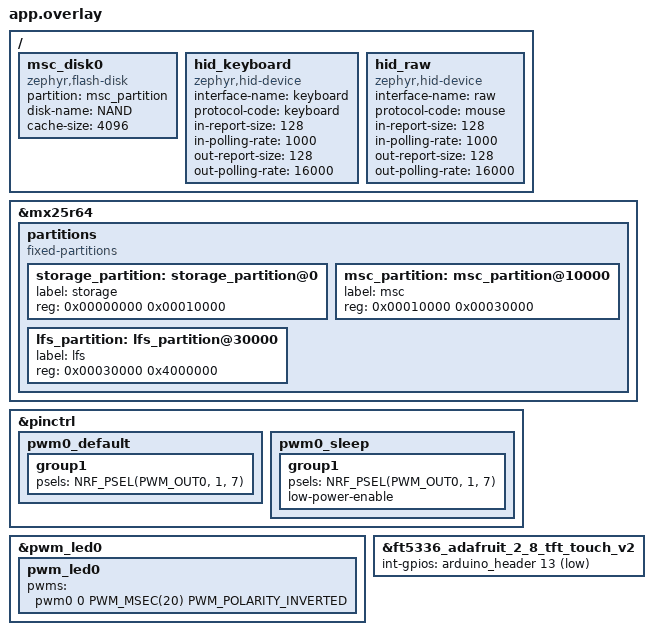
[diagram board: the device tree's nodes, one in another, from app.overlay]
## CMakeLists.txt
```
#-------------------------------------------------------------------------------
# Zephyr Example Application
#
# Copyright (c) 2021 Nordic Semiconductor ASA
# SPDX-License-Identifier: Apache-2.0

cmake_minimum_required(VERSION 3.13.1)
find_package(Zephyr REQUIRED HINTS $ENV{ZEPHYR_BASE})

project(app LANGUAGES C)

zephyr_include_directories(
    include
    # Disgusting hack
    ../../modules/fs/littlefs
)

add_subdirectory(src)
```

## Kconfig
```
# Copyright (c) 2021 Nordic Semiconductor ASA
# SPDX-License-Identifier: Apache-2.0
#
# This file is the application Kconfig entry point. All application Kconfig
# options can be defined here or included via other application Kconfig files.
# You can browse these options using the west targets menuconfig (terminal) or
# guiconfig (GUI).

menu "Zephyr"
source "Kconfig.zephyr"
endmenu

module = APP
module-str = APP
source "subsys/logging/Kconfig.template.log_config"

menu "USB sample options"
	depends on USB_DEVICE_STACK_NEXT

config ZIPPY_USBD_MANUFACTURER
	string "USB device sample manufacturer string"
	default "Zephyr Project"
	help
	  USB device sample manufacturer string.

config ZIPPY_USBD_PRODUCT
	string "USB device sample product string"
	default "USBD sample"
	help
	  USB device sample product stringa.

config ZIPPY_USBD_PID
	hex "USB device sample Product ID"
	default 0x0001
	help
	  USB device sample Product ID.

config ZIPPY_USBD_SELF_POWERED
	bool "USB device sample Self-powered attribute"
	default n
	help
	  Set the Self-powered attribute in the sample configuration.

config ZIPPY_USBD_REMOTE_WAKEUP
	bool "USB device sample Remote Wakeup attribute"
	help
	  Set the Remote Wakeup attribute in the sample configuration.

config ZIPPY_USBD_MAX_POWER
	int "USB device sample bMaxPower value"
	default 125
	range 0 250
	help
	  bMaxPower value in the sample configuration in 2 mA units.

config ZIPPY_USBD_INIT_PRIORITY
    int "USB device sample initialization priority"
    default 90
    help
      USB device sample initialization priority.

config ZIPPY_USBD_HID_KEYBOARD_INIT_PRIORITY
	int "USB device sample HID keyboard initialization priority"
	default 89
	help
	  USB device sample HID keyboard initialization priority.

config ZIPPY_USBD_HID_RAW_INIT_PRIORITY
	int "USB device sample HID raw initialization priority"
	default 89
	help
	  USB device sample HID raw initialization priority.

config ZIPPY_USBD_MSC_INIT_PRIORITY
	int "USB device sample MSC initialization priority"
	default 89
	help
	  USB device sample MSC initialization priority.

endmenu

menu "GRUB Commander"
	depends on USB_DEVICE_STACK_NEXT

config ZIPPY_GRUB_COMMANDER 
	bool "Enable GRUB Commander"
	imply FILE_SYSTEM
	imply FAT_FILESYSTEM_ELM
	imply FS_FATFS_LFN
	imply USBD_MSC_CLASS
	default n
	help
	  Enable GRUB Commander.

endmenu

menu "Audio Player"
	depends on USB_DEVICE_STACK_NEXT

config ZIPPY_AUDIO_PLAYER 
	bool "Enable Audio Player"
	imply USBD_HID_SUPPORT
	default n
	help
	  Enable Audio Player.

endmenu

menu "Audio Controller"
	depends on USB_DEVICE_STACK_NEXT

config ZIPPY_AUDIO_CONTROLLER 
	bool "Enable Audio Controller"
	imply USBD_HID_SUPPORT
	default n
	help
	  Enable Audio Controller.

endmenu

menu "Macros"
	depends on USB_DEVICE_STACK_NEXT

config ZIPPY_MACROS 
	bool "Enable Macros"
	imply USBD_HID_SUPPORT
	default n
	help
	  Enable Macros.

endmenu

menu "User Interface"
	depends on LVGL

config ZIPPY_UI_INIT_PRIORITY
	int "UI initialization priority"
	default 91
	help
	  UI initialization priority.

config ZIPPY_UI_TAB_INIT_PRIORITY
	int "UI tab initialization priority"
	default 92
	help
	  UI tab initialization priority.
	
choice 
	prompt "Select theme"

config ZIPPY_THEME_DEFAULT
	bool "Default"
	help
	  Default theme.

config ZIPPY_THEME_CUSTOM
	bool "Custom"
	help
	  Custom theme.

endchoice

endmenu
```

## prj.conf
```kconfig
# Copyright (c) 2021 Nordic Semiconductor ASA
# SPDX-License-Identifier: Apache-2.0
#
# This file contains selected Kconfig options for the application.

CONFIG_LV_Z_MEM_POOL_SIZE=32768
CONFIG_LV_Z_SHELL=y
CONFIG_MAIN_STACK_SIZE=4096

CONFIG_DISPLAY=y
CONFIG_DISPLAY_LOG_LEVEL_ERR=y

CONFIG_PWM=y

CONFIG_LOG=y
CONFIG_LOG_MODE_DEFERRED=y
CONFIG_SHELL=y

CONFIG_PM_DEVICE=y

CONFIG_LVGL=y
CONFIG_LV_USE_FLEX=y
CONFIG_LV_MEM_CUSTOM=y
CONFIG_LV_USE_LOG=y
CONFIG_LV_USE_LABEL=y
CONFIG_LV_USE_BTN=y
CONFIG_LV_USE_BTNMATRIX=y
CONFIG_LV_USE_TABVIEW=y
CONFIG_LV_USE_ARC=y
CONFIG_LV_USE_IMG=y
CONFIG_LV_USE_SLIDER=y
CONFIG_LV_USE_MONKEY=y
CONFIG_LV_USE_FS_LITTLEFS=y
CONFIG_LV_FS_LITTLEFS_LETTER=69
CONFIG_LV_FONT_MONTSERRAT_12_SUBPX=y
CONFIG_LV_Z_FLUSH_THREAD=y

CONFIG_LV_USE_PERF_MONITOR=y
CONFIG_LV_PERF_MONITOR_ALIGN_BOTTOM_RIGHT=y

# USB
CONFIG_UDC_BUF_POOL_SIZE=4096
CONFIG_UDC_BUF_COUNT=32
CONFIG_USB_DEVICE_STACK_NEXT=y
CONFIG_USBD_MSC_STACK_SIZE=2048
CONFIG_USBD_THREAD_STACK_SIZE=2048
CONFIG_USBD_HID_SUPPORT=y
CONFIG_USBD_HID_IN_BUF_COUNT=4
CONFIG_USBD_HID_OUT_BUF_COUNT=4
CONFIG_USBD_MSC_CLASS=y
CONFIG_USBD_MSC_LUNS_PER_INSTANCE=3

CONFIG_USBD_LOG_LEVEL_WRN=y
CONFIG_USBD_HID_LOG_LEVEL_DBG=y

CONFIG_GPIO=y
CONFIG_INPUT=y

CONFIG_FLASH=y
CONFIG_FLASH_MAP=y
CONFIG_DISK_DRIVER_FLASH=y
CONFIG_NVS=y

CONFIG_FILE_SYSTEM=y
CONFIG_FILE_SYSTEM_LITTLEFS=y
CONFIG_FAT_FILESYSTEM_ELM=y
CONFIG_FS_FATFS_LFN=y
CONFIG_FS_FATFS_MAX_LFN=128
CONFIG_NORDIC_QSPI_NOR_FLASH_LAYOUT_PAGE_SIZE=4096

CONFIG_DISK_DRIVER_SDMMC=n

CONFIG_DEBUG_OPTIMIZATIONS=y
CONFIG_DEBUG_INFO=y
CONFIG_DEBUG_THREAD_INFO=y

CONFIG_SYSTEM_WORKQUEUE_STACK_SIZE=4096

CONFIG_ZBUS=y

CONFIG_ZIPPY_AUDIO_CONTROLLER=y
CONFIG_ZIPPY_AUDIO_PLAYER=y
CONFIG_ZIPPY_GRUB_COMMANDER=y
CONFIG_ZIPPY_MACROS=y

CONFIG_ZIPPY_THEME_DEFAULT=y
CONFIG_INPUT=y
```

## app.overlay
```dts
/*
 * Copyright (c) 2023 Nordic Semiconductor ASA
 *
 * SPDX-License-Identifier: Apache-2.0
 */
/delete-node/ &storage_partition;

&mx25r64 {
	status = "okay";
	partitions {
		compatible = "fixed-partitions";
		#address-cells = <1>;
		#size-cells = <1>;

		storage_partition: storage_partition@0 {
			label = "storage";
			reg = <0x00000000 0x00010000>;
		};

		msc_partition: msc_partition@10000 {
			label = "msc";
			reg = <0x00010000 0x00030000>;
		};

		lfs_partition: lfs_partition@30000 {
			label = "lfs";
			reg = <0x00030000 0x4000000>;
		};
	};
};

/ {
	
	msc_disk0 {
		compatible = "zephyr,flash-disk";
		partition = <&msc_partition>;
		disk-name = "NAND";
		cache-size = <4096>;
	};

	hid_keyboard: hid_keyboard {
        status = "okay";
		compatible = "zephyr,hid-device";
		interface-name = "keyboard";
		protocol-code = "keyboard";
		in-report-size = <128>;
		in-polling-rate = <1000>;
		out-report-size = <128>;
		out-polling-rate = <16000>;
	};

	hid_raw: hid_raw {
		status = "okay";
		compatible = "zephyr,hid-device";
		interface-name = "raw";
		protocol-code = "mouse";
		in-report-size = <128>;
		in-polling-rate = <1000>;
		out-report-size = <128>;
		out-polling-rate = <16000>;
	};
};

&pinctrl {
	pwm0_default: pwm0_default {
		group1 {
			psels = <NRF_PSEL(PWM_OUT0, 1, 7)>;
		};
	};

	pwm0_sleep: pwm0_sleep {
		group1 {
			psels = <NRF_PSEL(PWM_OUT0, 1, 7)>;
			low-power-enable;
		};
	};
};

&pwm_led0 {
	pwm_led0 {
		pwms = <&pwm0 0 PWM_MSEC(20) PWM_POLARITY_INVERTED>;
	};
};

&ft5336_adafruit_2_8_tft_touch_v2 {
	/* Uncomment if IRQ line is available (requires to solder jumper) */
	int-gpios = <&arduino_header 13 GPIO_ACTIVE_LOW>;
};
```

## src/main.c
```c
/*
 * Copyright (c) 2018 Jan Van Winkel <jan.van_winkel@dxplore.eu>
 *
 * SPDX-License-Identifier: Apache-2.0
 */

#include <zephyr/device.h>
#include <zephyr/devicetree.h>
#include <zephyr/drivers/display.h>
#include <zephyr/drivers/gpio.h>

#include <nrfx_clock.h>

#include <lvgl.h>
#include <stdio.h>
#include <string.h>
#include <zephyr/kernel.h>
#include <lvgl_input_device.h>

#define LOG_LEVEL CONFIG_LOG_DEFAULT_LEVEL
#include <zephyr/logging/log.h>
LOG_MODULE_REGISTER(app);

static uint32_t count;

#ifdef CONFIG_GPIO
static struct gpio_dt_spec button_gpio = GPIO_DT_SPEC_GET_OR(
		DT_ALIAS(sw0), gpios, {0});
static struct gpio_callback button_callback;

static void button_isr_callback(const struct device *port,
				struct gpio_callback *cb,
				uint32_t pins)
{
	ARG_UNUSED(port);
	ARG_UNUSED(cb);
	ARG_UNUSED(pins);

	count = 0;
}
#endif /* CONFIG_GPIO */

#ifdef CONFIG_LV_Z_ENCODER_INPUT
static const struct device *lvgl_encoder =
	DEVICE_DT_GET(DT_COMPAT_GET_ANY_STATUS_OKAY(zephyr_lvgl_encoder_input));
#endif /* CONFIG_LV_Z_ENCODER_INPUT */

#ifdef CONFIG_LV_Z_KEYPAD_INPUT
static const struct device *lvgl_keypad =
	DEVICE_DT_GET(DT_COMPAT_GET_ANY_STATUS_OKAY(zephyr_lvgl_keypad_input));
#endif /* CONFIG_LV_Z_KEYPAD_INPUT */

static void lv_btn_click_callback(lv_event_t *e)
{
	ARG_UNUSED(e);

	count = 0;
}

int main(void)
{
    nrfx_clock_divider_set(NRF_CLOCK_DOMAIN_HFCLK, NRF_CLOCK_HFCLK_DIV_1);

	char count_str[11] = {0};
	const struct device *display_dev;
	lv_obj_t *hello_world_label;
	lv_obj_t *count_label;

	display_dev = DEVICE_DT_GET(DT_CHOSEN(zephyr_display));
	if (!device_is_ready(display_dev)) {
		LOG_ERR("Device not ready, aborting test");
		return 0;
	}

#ifdef CONFIG_GPIO
	if (gpio_is_ready_dt(&button_gpio)) {
		int err;

		err = gpio_pin_configure_dt(&button_gpio, GPIO_INPUT);
		if (err) {
			LOG_ERR("failed to configure button gpio: %d", err);
			return 0;
		}

		gpio_init_callback(&button_callback, button_isr_callback,
				   BIT(button_gpio.pin));

		err = gpio_add_callback(button_gpio.port, &button_callback);
		if (err) {
			LOG_ERR("failed to add button callback: %d", err);
			return 0;
		}

		err = gpio_pin_interrupt_configure_dt(&button_gpio,
						      GPIO_INT_EDGE_TO_ACTIVE);
		if (err) {
			LOG_ERR("failed to enable button callback: %d", err);
			return 0;
		}
	}
#endif /* CONFIG_GPIO */
    /* Create a Tab view object */
    lv_obj_t *tabview = lv_tabview_create(lv_scr_act(), LV_DIR_TOP, 20);

    /* Set styles for the tabview and tab buttons */
    lv_obj_set_style_bg_color(tabview, lv_palette_lighten(LV_PALETTE_RED, 2), 0);

#define STATE (LV_PART_ITEMS | LV_STATE_DEFAULT | LV_STATE_CHECKED)

    lv_obj_t *tab_buttons = lv_tabview_get_tab_btns(tabview); // Correct function to get tab buttons
    lv_obj_set_style_bg_color(tab_buttons, lv_color_hex(0x404040), LV_PART_ITEMS | LV_STATE_CHECKED);
    lv_obj_set_style_bg_color(tab_buttons, lv_color_hex(0x808080), LV_STATE_DEFAULT);
    lv_obj_set_style_text_color(tab_buttons, lv_color_hex(0x000000), STATE);
    lv_obj_set_style_border_width(tab_buttons, 2, STATE);
    lv_obj_set_style_border_side(tab_buttons, LV_BORDER_SIDE_FULL, STATE);
    lv_obj_set_style_border_color(tab_buttons, lv_color_hex(0x000000), STATE);
    // Note: Adjust the part and state if necessary for styling

    /* Add tabs */
    lv_obj_t *tab1 = lv_tabview_add_tab(tabview, "Tab 1");
    lv_obj_t *tab2 = lv_tabview_add_tab(tabview, "Tab 2");

    /* Add content to the tabs */
    lv_obj_t *label = lv_label_create(tab1);
    lv_label_set_text(label, "First tab");

    lv_obj_t *label2 = lv_label_create(tab2);
    lv_label_set_text(label2, "Second tab");

    lv_obj_clear_flag(lv_tabview_get_content(tabview), LV_OBJ_FLAG_SCROLLABLE);

	lv_task_handler();
	display_blanking_off(display_dev);

	while (1) {
		lv_task_handler();
		++count;
		k_sleep(K_MSEC(5));
	}
}
```
